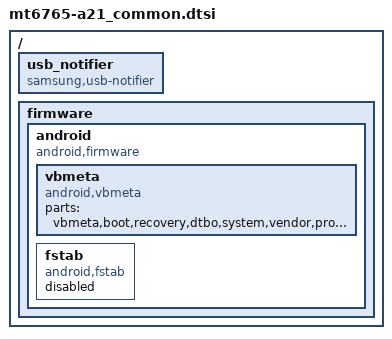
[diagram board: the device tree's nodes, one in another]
/* Generated by WT for S1 project board 
 * If these files should be chaned, then please make a sync with WT or MTK
*/

/* Add Samsung configuration over here */
/ {
	fragment@model {
		target-path = "/";
		__overlay__ {
			usb_notifier {
				compatible = "samsung,usb-notifier";
			};
			
			firmware {
				android {
					compatible = "android,firmware";
					vbmeta {
						compatible = "android,vbmeta";
						parts = "vbmeta,boot,recovery,dtbo,system,vendor,product,odm,prism,optics";
					};

					fstab {
						compatible = "android,fstab";
						status = "disabled";
					};
				};
			};
		};
	};
};

